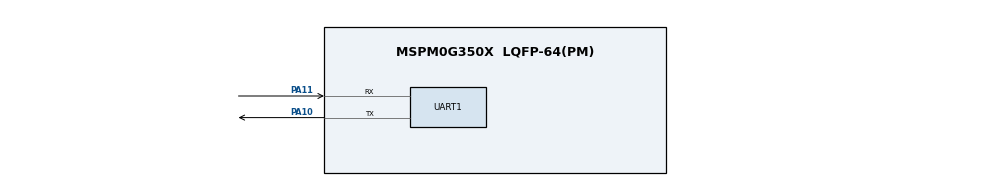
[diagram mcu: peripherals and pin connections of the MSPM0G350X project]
/**
 * @cliArgs --device "MSPM0G350X" --part "Default" --package "LQFP-64(PM)" --product "mspm0_sdk@2.04.00.06"
 * @versions {"tool":"1.21.1+3772"}
 */

/**
 * Import the modules used in this configuration.
 */
const GPIO   = scripting.addModule("/ti/driverlib/GPIO", {}, false);
const GPIO1  = GPIO.addInstance();
const GPIO2  = GPIO.addInstance();
const SYSCTL = scripting.addModule("/ti/driverlib/SYSCTL");
const UART   = scripting.addModule("/ti/driverlib/UART", {}, false);
const UART1  = UART.addInstance();

/**
 * Write custom configuration values to the imported modules.
 */
GPIO1.$name                          = "GPIO_OLED";
GPIO1.associatedPins.create(5);
GPIO1.associatedPins[0].$name        = "SCL";
GPIO1.associatedPins[0].assignedPort = "PORTA";
GPIO1.associatedPins[0].assignedPin  = "17";
GPIO1.associatedPins[1].$name        = "SDA";
GPIO1.associatedPins[1].assignedPort = "PORTB"; 
GPIO1.associatedPins[1].assignedPin  = "15";
GPIO1.associatedPins[2].$name        = "RST";
GPIO1.associatedPins[2].assignedPort = "PORTB";
GPIO1.associatedPins[2].assignedPin  = "16";
GPIO1.associatedPins[3].$name        = "DC";
GPIO1.associatedPins[3].assignedPort = "PORTB";
GPIO1.associatedPins[3].assignedPin  = "17";
GPIO1.associatedPins[4].$name        = "CS";
GPIO1.associatedPins[4].assignedPort = "PORTB";
GPIO1.associatedPins[4].assignedPin  = "20";

GPIO2.$name                          = "GPIO_KEY";
GPIO2.associatedPins.create(4);
GPIO2.associatedPins[0].$name        = "KEY1";
GPIO2.associatedPins[0].assignedPort = "PORTB";
GPIO2.associatedPins[0].assignedPin  = "12";
GPIO2.associatedPins[0].direction    = "INPUT";
GPIO2.associatedPins[0].enableConfig = true;
GPIO2.associatedPins[0].internalResistor = "PULL_UP";
GPIO2.associatedPins[1].$name        = "KEY2";
GPIO2.associatedPins[1].assignedPort = "PORTB";
GPIO2.associatedPins[1].assignedPin  = "8";
GPIO2.associatedPins[1].direction    = "INPUT";
GPIO2.associatedPins[1].enableConfig = true;
GPIO2.associatedPins[1].internalResistor = "PULL_UP";
GPIO2.associatedPins[2].$name        = "KEY3";
GPIO2.associatedPins[2].assignedPort = "PORTB";
GPIO2.associatedPins[2].assignedPin  = "9";
GPIO2.associatedPins[2].direction    = "INPUT";
GPIO2.associatedPins[2].enableConfig = true;
GPIO2.associatedPins[2].internalResistor = "PULL_UP";
GPIO2.associatedPins[3].$name        = "KEY4";
GPIO2.associatedPins[3].assignedPort = "PORTB";
GPIO2.associatedPins[3].assignedPin  = "10";
GPIO2.associatedPins[3].direction    = "INPUT";
GPIO2.associatedPins[3].enableConfig = true;
GPIO2.associatedPins[3].internalResistor = "PULL_UP";

const Board = scripting.addModule("/ti/driverlib/Board", {}, false);

SYSCTL.forceDefaultClkConfig = true;

UART1.$name                    = "UART_0";
UART1.peripheral.rxPin.$assign = "PA11";
UART1.peripheral.txPin.$assign = "PA10";
UART1.txPinConfig.$name        = "ti_driverlib_gpio_GPIOPinGeneric0";
UART1.rxPinConfig.$name        = "ti_driverlib_gpio_GPIOPinGeneric1";

/**
 * Pinmux solution for unlocked pins/peripherals. This ensures that minor changes to the automatic solver in a future
 * version of the tool will not impact the pinmux you originally saw.  These lines can be completely deleted in order to
 * re-solve from scratch.
 */
GPIO1.associatedPins[0].pin.$suggestSolution = "PA17";
GPIO1.associatedPins[1].pin.$suggestSolution = "PB15";
GPIO1.associatedPins[2].pin.$suggestSolution = "PB16";
GPIO1.associatedPins[3].pin.$suggestSolution = "PB17";
GPIO1.associatedPins[4].pin.$suggestSolution = "PB20";
GPIO2.associatedPins[0].pin.$suggestSolution = "PB12";
GPIO2.associatedPins[1].pin.$suggestSolution = "PB8";
GPIO2.associatedPins[2].pin.$suggestSolution = "PB9";
GPIO2.associatedPins[3].pin.$suggestSolution = "PB10";
Board.peripheral.$suggestSolution            = "DEBUGSS";
Board.peripheral.swclkPin.$suggestSolution   = "PA20";
Board.peripheral.swdioPin.$suggestSolution   = "PA19";
SYSCTL.peripheral.$suggestSolution           = "SYSCTL";
UART1.peripheral.$suggestSolution            = "UART0";
